# RT584ZCM33 register map
Series: ARMv8-M Mainline; File version: 1.0
CPU: CM33 r0p0, little endian, MPU, no FPU, VTOR, 3 interrupt priority bits
Registers are 32-bit, read-write, reset 0x0 unless marked. A register's access mark holds for its fields unless they carry their own. Offsets are from the block's base; [hi:lo] are bit positions.

## SEC_CTRL_Secure — SEC_CTRL Secure Register block
Base 0x50003000
0x00 SEC_FLASH_S_REG reset 0x10000 — sec flash s
  [18:0] sec_flash_s_stop — Set the stop of secure region of Flash in the unit of 32 bytes. This will define the secure region of Flash from 0x10000000 to (0x10000000+sec_flash_s_stop*32-1)
0x04 SEC_FLASH_NSC0_REG reset 0x10000 — sec flash nsc0
  [18:0] sec_flash_nsc_start — Set the start of non-secure callable (NSC) region of Flash in the unit of 32 bytes. The NSC region of Flash is start from (0x10000000+sec_flash_nsc_start*32) to (0x10000000+sec_flash_nsc_stop*32 -1). Be aware that both sec_flash_nsc_start and sec_flash_nsc_stop MUST within the sec_flash_s_stop.
0x08 SEC_FLASH_NSC1_REG reset 0x10000 — sec flash nsc1
  [18:0] sec_flash_nsc_stop — Set the stop of non-secure callable (NSC) region of Flash in the unit of 32 bytes. The NSC region of Flash is start from (0x10000000+sec_flash_nsc_start*32) to (0x10000000+sec_flash_nsc_stop*32 -1). Be aware that both sec_flash_nsc_start and sec_flash_nsc_stop MUST within the sec_flash_s_stop.
0x0C SEC_FLASH_NS_REG reset 0x10000 — sec flash ns
  [18:0] sec_flash_ns_stop — Set the stop of non-secure (NS) region of Flash in the unit of 32 bytes. The NS region of Flash is start from (0x00000000+sec_flash_s_stop*32) to (0x00000000+sec_flash_ns_stop*32 -1).
0x10 SEC_RAM_S_REG reset 0x2C00 — sec ram s
  [14:0] sec_ram_s_stop — Set the stop of secure region of RAM in the unit of 32 bytes. This will define the secure region of RAM from 0x30000000 to (0x30000000+sec_ram_s_stop*32-1)
0x14 SEC_RAM_NSC0_REG reset 0x2C00 — sec ram nsc0
  [14:0] sec_ram_nsc_start — Set the start of non-secure callable (NSC) region of RAM in the unit of 32 bytes. The NSC region of RAM is start from (0x30000000+sec_ram_nsc_start*32) to (0x30000000+sec_ram_nsc_stop*32 -1). Be aware that both sec_ram_nsc_start and sec_ram_nsc_stop MUST within the sec_ram_s_stop.
0x18 SEC_RAM_NSC1_REG reset 0x2C00 — sec ram nsc1
  [14:0] sec_ram_nsc_stop — Set the stop of non-secure callable (NSC) region of RAM in the unit of 32 bytes. The NSC region of RAM is start from (0x30000000+sec_ram_nsc_start*32) to (0x30000000+sec_ram_nsc_stop*32 -1). Be aware that both sec_ram_nsc_start and sec_ram_nsc_stop MUST within the sec_ram_s_stop.
0x1C SEC_RAM_NS_REG reset 0x2C00 — sec ram ns
  [14:0] sec_ram_ns_stop — Set the stop of non-secure (NS) region of RAM in the unit of 32 bytes. The NS region of RAM is start from (0x00000000+sec_ram_s_stop*32) to (0x00000000+sec_ram_ns_stop*32 -1).
0x20 SEC_PERI_ATTR0_REG — Set the corresponding peripheral non-secure. Please refer to the MemoryMap sheet for the bit map. 0: secure 1: non-secure
0x24 SEC_PERI_ATTR1_REG — Set the corresponding peripheral non-secure. Please refer to the MemoryMap sheet for the bit map. 0: secure 1: non-secure
0x28 SEC_PERI_ATTR2_REG — sec peri attr2
  [7:0] sec_peri_ns2 — Set the corresponding peripheral non-secure. Please refer to the MemoryMap sheet for the bit map. 0: secure 1: non-secure
    0=B_0_to_7 (Set the corresponding peripheral non-secure. Please refer to the MemoryMap sheet for the bit map. 0: secure 1: non-secure)
0x2C SEC_IDAU_CTRL_REG — sec idau ctrl
  [0] sec_idau_en — Enable Implementation Defined Attribution Unit (IDAU) and related security control units. 0: disable 1: enable
    0=B_0_ITEM0 (disable); 1=B_0_ITEM1 (enable)
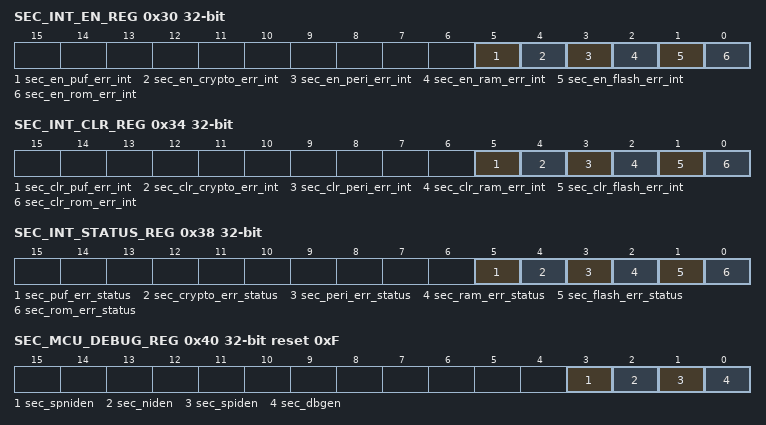
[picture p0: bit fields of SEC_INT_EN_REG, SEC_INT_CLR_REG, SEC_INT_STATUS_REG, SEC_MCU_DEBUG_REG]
0x30 SEC_INT_EN_REG — sec int en
  [5] sec_en_puf_err_int — Enable PUF/OTP security error interrupt
    0=B_5 (Enable PUF/OTP security error interrupt)
  [4] sec_en_crypto_err_int — Enable Crypto Engine security error interrupt
    0=B_4 (Enable Crypto Engine security error interrupt)
  [3] sec_en_peri_err_int — Enable Peripheral security error interrupt
    0=B_3 (Enable Peripheral security error interrupt)
  [2] sec_en_ram_err_int — Enable RAM security error interrupt
    0=B_2 (Enable RAM security error interrupt)
  [1] sec_en_flash_err_int — Enable Flash security error interrupt
    0=B_1 (Enable Flash security error interrupt)
  [0] sec_en_rom_err_int — Enable ROM security error interrupt
    0=B_0 (Enable ROM security error interrupt)
0x34 SEC_INT_CLR_REG wo — sec int clr
  [5] sec_clr_puf_err_int — Clear PUF/OTP security error interrupt
    0=B_5 (Clear PUF/OTP security error interrupt)
  [4] sec_clr_crypto_err_int — Clear Crypto Engine security error interrupt
    0=B_4 (Clear Crypto Engine security error interrupt)
  [3] sec_clr_peri_err_int — Clear Peripheral security error interrupt
    0=B_3 (Clear Peripheral security error interrupt)
  [2] sec_clr_ram_err_int — Clear RAM security error interrupt
    0=B_2 (Clear RAM security error interrupt)
  [1] sec_clr_flash_err_int — Clear Flash security error interrupt
    0=B_1 (Clear Flash security error interrupt)
  [0] sec_clr_rom_err_int — Clear ROM security error interrupt
    0=B_0 (Clear ROM security error interrupt)
0x38 SEC_INT_STATUS_REG ro — sec int status
  [5] sec_puf_err_status — PUF/OTP security status
    0=B_5 (PUF/OTP security status)
  [4] sec_crypto_err_status — Crypto Engine security status
    0=B_4 (Crypto Engine security status)
  [3] sec_peri_err_status — Peripheral security status
    0=B_3 (Peripheral security status)
  [2] sec_ram_err_status — RAM security error status
    0=B_2 (RAM security error status)
  [1] sec_flash_err_status — Flash security error status
    0=B_1 (Flash security error status)
  [0] sec_rom_err_status — Flash security error status
    0=B_0 (Flash security error status)
0x40 SEC_MCU_DEBUG_REG reset 0xF — sec mcu debug
  [3] sec_spniden — MCU secure non-invasive debug enable
    0=B_3 (MCU secure non-invasive debug enable)
  [2] sec_niden — MCU non-invasive debug enable
    0=B_2 (MCU non-invasive debug enable)
  [1] sec_spiden — MCU secure invasive debug enable
    0=B_1 (MCU secure invasive debug enable)
  [0] sec_dbgen — MCU invasive debug enable
    0=B_0 (MCU invasive debug enable)
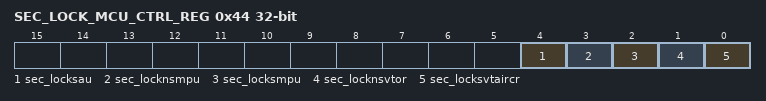
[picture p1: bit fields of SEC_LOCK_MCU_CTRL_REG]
0x44 SEC_LOCK_MCU_CTRL_REG — sec lock mcu ctrl
  [4] sec_locksau — Cortex-M33 LOCKSAU 0: Unlocks these registers 1: Disables writes to the SAU_CTRL, SAU_RNR, SAU_RBAR and SAU_RLAR registers.
    0=B_4_ITEM0 (Unlocks these registers); 1=B_4_ITEM1 (Disables writes to the SAU_CTRL, SAU_RNR, SAU_RBAR and SAU_RLAR registers.)
  [3] sec_locknsmpu — Cortex-M33 LOCKNSMPU 0: Unlocks these registers 1: Disables writes to the MPU_CTRL_NS, MPU_RNR_NS, MPU_RBAR_NS, MPU_RLAR_NS, MPU_RBAR_A_NSn and MPU_RLAR_A_NSn registers.
    0=B_3_ITEM0 (Unlocks these registers); 1=B_3_ITEM1 (Disables writes to the MPU_CTRL_NS, MPU_RNR_NS, MPU_RBAR_NS, MPU_RLAR_NS, MPU_RBAR_A_NSn and MPU_RLAR_A_NSn registers.)
  [2] sec_locksmpu — Cortex-M33 LOCKSMPU 0: Unlocks these registers 1: Disables writes to the MPU_CTRL, MPU_RNR, MPU_RBAR, MPU_RLAR, MPU_RBAR_An and MPU_RLAR_An registers.
    0=B_2_ITEM0 (Unlocks these registers); 1=B_2_ITEM1 (Disables writes to the MPU_CTRL, MPU_RNR, MPU_RBAR, MPU_RLAR, MPU_RBAR_An and MPU_RLAR_An registers.)
  [1] sec_locknsvtor — Cortex-M33 LOCKNSVTOR 0: Unlocks this register 1: Disables writes to the VTOR_NS register.
    0=B_1_ITEM0 (Unlocks this register); 1=B_1_ITEM1 (Disables writes to the VTOR_NS register.)
  [0] sec_locksvtaircr — Cortex-M33 LOCKSVTAIRCR 0: Unlocks these registers 1: Disables writes to the VTOR_S, AIRCR.PRIS and AIRCR.BFHFNMINS registers.
    0=B_0_ITEM0 (Unlocks these registers); 1=B_0_ITEM1 (Disables writes to the VTOR_S, AIRCR.PRIS and AIRCR.BFHFNMINS registers.)
0x48 SEC_OTP_WRITE_PROTECT_REG — Set the correct key (0x28514260) to enable OTP write.
